# MSS_CSI2 register map
Vendor: Texas Instruments
Peripheral module from a debugger description file (folder awr2x44p).
Registers are 32-bit, access per field, no defined reset value unless marked. A register's access mark holds for its fields unless they carry their own. Offsets are as the file gives them; lines under a group give offsets from that group; [hi:lo] are bit positions; {n}, {i} and the like mark numbered series; 'fields as' and 'values as' point back to an identical list; <NAME> marks a mode.

## MSS_CSI2
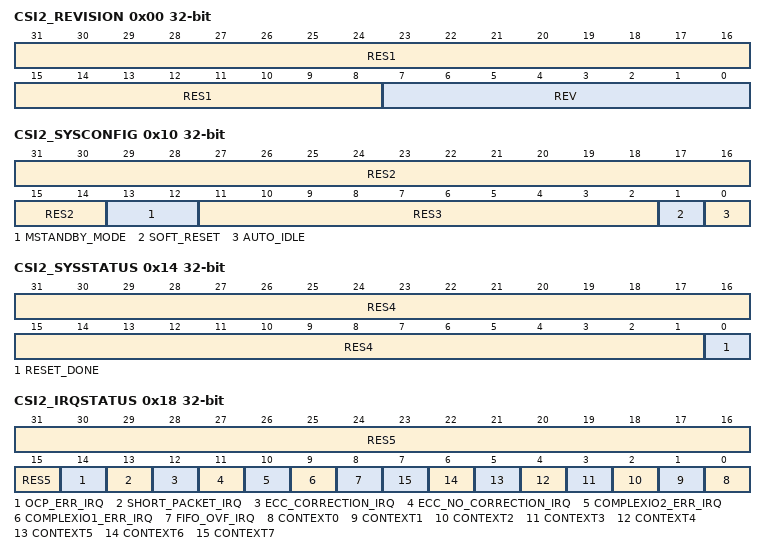
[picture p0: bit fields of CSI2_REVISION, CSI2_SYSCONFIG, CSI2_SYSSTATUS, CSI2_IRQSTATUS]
0x00 CSI2_REVISION ro — MODULE REVISION This register contains the IP revision code in binary coded digital. For example we have: 0x01 = revision 0.1 and 0x21 = revision 2.1
  [31:8] RES1 — RESERVE FIELD
  [7:0] REV — IP revision [7:4] Major revision [3:0] Minor revision
0x10 CSI2_SYSCONFIG — SYSTEM CONFIGURATION REGISTER This register is the OCP-socket system configuration register.
  [31:14] RES2 ro — RESERVE FIELD
  [13:12] MSTANDBY_MODE rw — RESERVE FIELD
  [11:2] RES3 ro — RESERVE FIELD
  [1] SOFT_RESET rw — Software reset. Set the bit to 1 to trigger a module reset. The bit is automatically reset by the hw. During reads return 0. 0: Normal mode. 1: The module is reset
  [0] AUTO_IDLE rw — Internal OCP gating strategy 0: OCP clock is free-running. 1: Automatic OCP clock gating strategy is applied based on the OCP interface activity.
0x14 CSI2_SYSSTATUS ro — SYSTEM STATUS REGISTER This register provides status information about the module excluding the interrupt status register.
  [31:1] RES4 — RESERVE FIELD
  [0] RESET_DONE — Internal reset monitoring Read 0x1: Reset completed. Read 0x0: Internal module reset is on going.
0x18 CSI2_IRQSTATUS — INTERRUPT STATUS REGISTER - All contexts This register associates one bit for each context in order to determine which context has generated the interrupt. The context shall be enabled for events to be generated on that context. If the
  [31:15] RES5 ro — RESERVE FIELD
  [14] OCP_ERR_IRQ rw — OCP Error Interrupt 0: READS: Event is false. WRITES: Status bit unchanged. 1: READS: Event is true (pending). WRITES: Status bit is reset. (RW W1toClr)
  [13] SHORT_PACKET_IRQ rw — Short packet reception status (other than synch events: Line Start, Line End, Frame Start, and Frame End: data type between 0x8 and x0F only shall be considered). 0: READS: Event is false. WRITES: Status bit unchanged. 1: READS: Event is true (pending). WRITES: Status bit is reset. (RW W1toClr)
  [12] ECC_CORRECTION_IRQ rw — ECC has been used to do the correction of the only 1-bit error status (short packet only). 0: READS: Event is false. WRITES: Status bit unchanged. 1: READS: Event is true (pending). WRITES: Status bit is reset. - (RW W1toClr)
  [11] ECC_NO_CORRECTION_IRQ rw — ECC error status (short and long packets). No correction of the header because of more than 1-bit error. 0: READS: Event is false. WRITES: Status bit unchanged. 1: READS: Event is true (pending). WRITES: Status bit is reset. - (RW W1toClr)
  [10] COMPLEXIO2_ERR_IRQ ro — RESERVE FIELD
  [9] COMPLEXIO1_ERR_IRQ ro — Error signaling from Complex IO #1: status of the PHY errors received from the complex IO #1 (events are defined in CSI2_COMPLEXIO1_IRQSTATUS for the 1st complex IO). Read 0: READS: Event is false. Read 1: READS: Event is true (pending).
  [8] FIFO_OVF_IRQ rw — FIFO overflow error status. 0: READS: Event is false. WRITES: Status bit unchanged. 1: READS: Event is true (pending). WRITES: Status bit is reset. - (RW W1toClr)
  [n] CONTEXT{n} ro (n=0..7) — Context {n} Read 0: READS: Event is false. Read 1: READS: Event is true (pending).
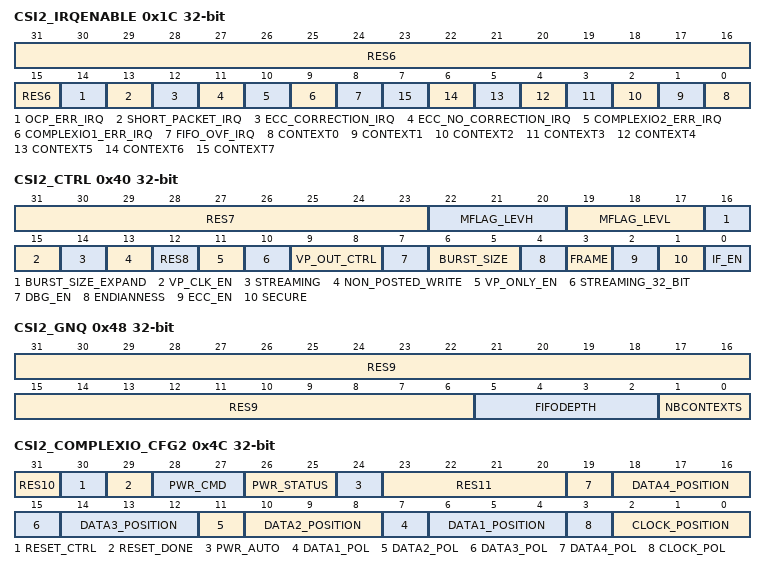
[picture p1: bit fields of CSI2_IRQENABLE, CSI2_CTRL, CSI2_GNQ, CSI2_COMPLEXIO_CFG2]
0x1C CSI2_IRQENABLE — INTERRUPT ENABLE REGISTER - All contexts This register associates one bit for each context in order to enable/disable each context individually.
  [31:15] RES6 ro — RESERVE FIELD
  [14] OCP_ERR_IRQ rw — OCP Error Interrupt 0: Event is masked 1: Event generates an interrupt when it occurs
  [13] SHORT_PACKET_IRQ rw — Short packet reception (other than synch events: Line Start, Line End, Frame Start, and Frame End: data type between 0x8 and x0F only shall be considered). 0: Event is masked 1: Event generates an interrupt when it occurs
  [12] ECC_CORRECTION_IRQ rw — ECC has been used to correct the only 1-bit error (short packet only). 0: Event is masked 1: Event generates an interrupt when it occurs
  [11] ECC_NO_CORRECTION_IRQ rw — ECC error (short and long packets). No correction of the header because of more than 1-bit error. 0: Event is masked 1: Event generates an interrupt when it occurs
  [10] COMPLEXIO2_ERR_IRQ rw — RESERVED
  [9] COMPLEXIO1_ERR_IRQ rw — Error signaling from Complex IO #1: the interrupt is triggered when any error is received from the complex IO #1 (events are defined in CSI2_COMPLEXIO1_IRQSTATUS for the 1st complex IO). 0: Event is masked 1: Event generates an interrupt when it occurs
  [8] FIFO_OVF_IRQ rw — FIFO overflow enable 0: Event is masked 1: Event generates an interrupt when it occurs
  [n] CONTEXT{n} rw (n=0..7) — Context {n} 0: Event is masked 1: Event generates an interrupt when it occurs
0x40 CSI2_CTRL — GLOBAL CONTROL REGISTER This register controls the CSI2 RECEIVER module. This register shall not be modified dynamically (except IF_EN bit field).
  [31:23] RES7 ro — RESERVE FIELD
  [22:20] MFLAG_LEVH rw — RESERVE FIELD
  [19:17] MFLAG_LEVL rw — RESERVE FIELD
  [16] BURST_SIZE_EXPAND rw — Sets the DMA burst size on the L3 interconnect. 0: Use the burst size defined in the BURST_SIZE register 1: Allow generation of 16x64-bit bursts
  [15] VP_CLK_EN rw — RESERVE FIELD
  [14] STREAMING rw — Streaming mode 0: Disable 1: Enable
  [13] NON_POSTED_WRITE rw — Not Posted Writes 0: Disable 1: Enable
  [12] RES8 ro — RESERVE FIELD
  [11] VP_ONLY_EN rw — RESERVE FIELD
  [10] STREAMING_32_BIT rw — Indicates if 64-bit or 32-bit streaming burst is used. Valid only if CSI2_CTRL.STREAMING=1 0: 64-bit streaming burst is used; byte enable pattern is 0xFF 1: 32-bit streaming burst is used; byte enable pattern is 0x0F
  [9:8] VP_OUT_CTRL rw — RESERVE FIELD
  [7] DBG_EN rw — Enables the debug mode. 0: Disable 1: Enable
  [6:5] BURST_SIZE rw — Sets the DMA burst size on the L3 interconnect. 0x0: 1x64 OCP writes 0x1: 2x64 OCP writes 0x2: 4x64 OCP writes 0x3: 8x64 OCP writes
  [4] ENDIANNESS rw — Select endianness for YUV422 8 bit and YUV420 legacy formats. 0: Use native MIPI CSI2 endianness: Little endian for all formats except for YUV422 8b and YUV420 Legacy which a big endian. 1: Store all pixel formats little endian.
  [3] FRAME rw — Set the modality in which IF_EN works. 0: If IF_EN = 0 the interface is disabled immediately. 1: If IF_EN = 1 the interface is disabled after all FEC sync code have been received for the active contexts.
  [2] ECC_EN rw — Enables the Error Correction Code check for the received header (short and long packets for all virtual channel ids). 0: Disabled 1: Enabled
  [1] SECURE rw — RESERVE FIELD
  [0] IF_EN rw — Enables the physical interface to the module. 0: The interface is disabled. If FRAME = 0, it is disabled immediately. If FRAME = 1, it is disabled when each context has received the FEC sync code. 1: The interface is enabled immediately, the data acquisition starts on the next FSC sync code. Writing '1' to this register when the current value is '0' has the effect to clear the output FIFO. The pixel data of the following frame will be written in the PING buffer, i.e., the CSI2_CTX_CTRL.PING_PONG bits are reset to '0' as well.
0x44 CSI2_DBG_H wo — DEBUG REGISTER (Header) This register provides a way to debug the CSI2 RECEIVER module with no image sensor connected to the module. The debug mode is enabled by CSI2_CTRL.DBG_EN. Only full 32-bit values shall be written. The register is
  [31:0] DBG — 32-bit input value.
0x48 CSI2_GNQ ro — GENERIC PARAMETER REGISTER This register provide a way to read the generic parameters used in the design.
  [31:6] RES9 — RESERVE FIELD
  [5:2] FIFODEPTH — Output FIFO size in multiple of 68 bits. Read 0x2: 8x 68 bits Read 0x3: 16x 68 bits Read 0x4: 32x 68 bits Read 0x5: 64x 68 bits Read 0x6: 128 x 68 bits Read 0x7: 256 x 68 bits
  [1:0] NBCONTEXTS — Number of contexts supported by the module. Read 0x0: 1 Context Read 0x1: 2 Contexts Read 0x2: 4 Contexts Read 0x3: 8 Contexts
0x4C CSI2_COMPLEXIO_CFG2 — COMPLEX IO CONFIGURATION REGISTER for the complex IO #2 This register contains the lane configuration for the order and position of the lanes (clock and data) and the polarity order for the control of the PHY differential signals in addit
  [31] RES10 ro — RESERVE FIELD
  [30] RESET_CTRL rw — RESERVE FIELD
  [29] RESET_DONE ro — RESERVE FIELD
  [28:27] PWR_CMD rw — RESERVE FIELD
  [26:25] PWR_STATUS ro — RESERVE FIELD
  [24] PWR_AUTO rw — RESERVE FIELD
  [23:20] RES11 ro — RESERVE FIELD
  [4n+3] DATA{n}_POL rw (n=1..4) — RESERVE FIELD
  [4n+2:4n] DATA{n}_POSITION rw (n=1..4) — RESERVE FIELD
  [3] CLOCK_POL rw — RESERVE FIELD
  [2:0] CLOCK_POSITION rw — RESERVE FIELD
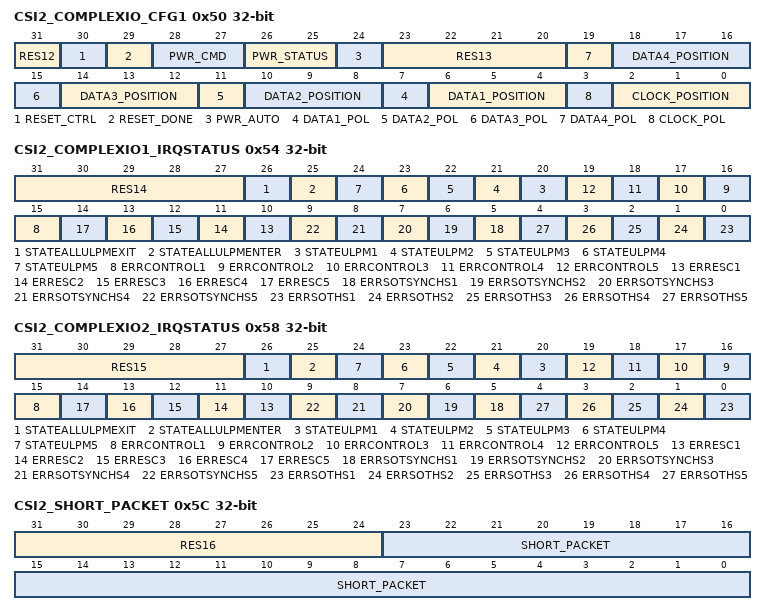
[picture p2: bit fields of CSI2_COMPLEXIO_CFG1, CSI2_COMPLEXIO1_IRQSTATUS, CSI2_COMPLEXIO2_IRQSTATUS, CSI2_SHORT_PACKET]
0x50 CSI2_COMPLEXIO_CFG1 — COMPLEXIO CONFIGURATION REGISTER for the complex IO #1 This register contains the lane configuration for the order and position of the lanes (clock and data) and the polarity order for the control of the PHY differential signals in additi
  [31] RES12 ro — RESERVE FIELD
  [30] RESET_CTRL rw — Controls the reset of the complex IO 0: Complex IO reset active. 1: Complex IO reset de-asserted.
  [29] RESET_DONE ro — Internal reset monitoring of the power domain using the PPI byte clock from the complex io Read 0: Internal module reset is on going. Read 1: Reset completed.
  [28:27] PWR_CMD rw — Command for power control of the complex io 0x0: Command to change to OFF state 0x1: Command to change to ON state 0x2: Command to change to Ultra Low Power state
  [26:25] PWR_STATUS ro — Status of the power control of the complex io Read 0x0: Complex IO in OFF state Read 0x1: Complex IO in ON state Read 0x2: Complex IO in Ultra Low Power state
  [24] PWR_AUTO rw — Automatic switch between ULP and ON states based on ULPM signals from complex iO 0: Disable 1: Enable
  [23:20] RES13 ro — RESERVE FIELD
  [4n+3] DATA{n}_POL rw (n=1..4) — +/- differential pin order of DATA lane {n}. 0: +/- pin order 1: -/+ pin order
  [18:16] DATA4_POSITION rw — Position and order of the DATA lane 4. The values 6 and 7 are reserved. 0x0: Not used/connected 0x1: Data lane 4 is at the position 1. 0x2: Data lane 4 is at the position 2. 0x3: Data lane 4 is at the position 3. 0x4: Data lane 4 is at the position 4. 0x5: Data lane 4 is at the position 5.
  [14:12] DATA3_POSITION rw — Position and order of the DATA lane 3. The values 6 and 7 are reserved. 0x0: Not used/connected 0x1: Data lane 3 is at the position 1. 0x2: Data lane 3 is at the position 2. 0x3: Data lane 3 is at the position 3. 0x4: Data lane 3 is at the position 4. 0x5: Data lane 3 is at the position 5.
  [10:8] DATA2_POSITION rw — Position and order of the DATA lane 2. The values 6 and 7 are reserved. 0x0: Not used/connected 0x1: Data lane 2 is at the position 1. 0x2: Data lane 2 is at the position 2. 0x3: Data lane 2 is at the position 3. 0x4: Data lane 2 is at the position 4. 0x5: Data lane 2 is at the position 5.
  [6:4] DATA1_POSITION rw — Position and order of the DATA lane 1. 0, 6 and 7 are reserved. The data lane 1 is always present. 0x1: Data lane 1 is at the position 1. 0x2: Data lane 1 is at the position 2. 0x3: Data lane 1 is at the position 3. 0x4: Data lane 1 is at the position 4. 0x5: Data lane 1 is at the position 5.
  [3] CLOCK_POL rw — +/- differential pin order of CLOCK lane. 0: +/- pin order 1: -/+ pin order
  [2:0] CLOCK_POSITION rw — Position and order of the CLOCK lane. 0, 6 and 7 are reserved. The clock lane is always present. 0x1: Clock lane is at the position 1. 0x2: Clock lane is at the position 2. 0x3: Clock lane is at the position 3. 0x4: Clock lane is at the position 4. 0x5: Clock lane is at the position 5.
0x54 CSI2_COMPLEXIO1_IRQSTATUS — INTERRUPT STATUS REGISTER - All errors from complex IO #1
  [31:27] RES14 ro — RESERVE FIELD
  [26] STATEALLULPMEXIT rw — At least one of the active lanes has exit the ULPM 0: READS: Event is false. WRITES: Status bit unchanged. 1: READS: Event is true (pending). WRITES: Status bit is reset. - (RW W1toClr)
  [25] STATEALLULPMENTER rw — All active lanes are entering in ULPM. 0: READS: Event is false. WRITES: Status bit unchanged. 1: READS: Event is true (pending). WRITES: Status bit is reset. - (RW W1toClr)
  [n+19] STATEULPM{n} rw (n=1..5) — Lane #{n} in Ultra Low Power Mode 0: READS: Event is false. WRITES: Status bit unchanged. 1: READS: Event is true (pending). WRITES: Status bit is reset. - (RW W1toClr)
  [n+14] ERRCONTROL{n} rw (n=1..5) — Control error for lane #{n} 0: READS: Event is false. WRITES: Status bit unchanged. 1: READS: Event is true (pending). WRITES: Status bit is reset. - (RW W1toClr)
  [n+9] ERRESC{n} rw (n=1..5) — Escape entry error for lane #{n} 0: READS: Event is false. WRITES: Status bit unchanged. 1: READS: Event is true (pending). WRITES: Status bit is reset. - (RW W1toClr)
  [n+4] ERRSOTSYNCHS{n} rw (n=1..5) — Start of transmission sync error for lane #{n} 0: READS: Event is false. WRITES: Status bit unchanged. 1: READS: Event is true (pending). WRITES: Status bit is reset. - (RW W1toClr)
  [n-1] ERRSOTHS{n} rw (n=1..5) — Start of transmission error for lane #{n} 0: READS: Event is false. WRITES: Status bit unchanged. 1: READS: Event is true (pending). WRITES: Status bit is reset. - (RW W1toClr)
0x58 CSI2_COMPLEXIO2_IRQSTATUS — INTERRUPT STATUS REGISTER - All errors from complex IO #2
  [31:27] RES15 ro — RESERVE FIELD
  [26] STATEALLULPMEXIT rw — RESERVE FIELD
  [25] STATEALLULPMENTER rw — RESERVE FIELD
  [n+19] STATEULPM{n} rw (n=1..5) — RESERVE FIELD
  [n+14] ERRCONTROL{n} rw (n=1..5) — RESERVE FIELD
  [n+9] ERRESC{n} rw (n=1..5) — RESERVE FIELD
  [n+4] ERRSOTSYNCHS{n} rw (n=1..5) — RESERVE FIELD
  [n-1] ERRSOTHS{n} rw (n=1..5) — RESERVE FIELD
0x5C CSI2_SHORT_PACKET ro — SHORT PACKET INFORMATION - This register sets the 24-bit DATA_ID + Short Packet Data Field when the data type is between 0x8 and x0F
  [31:24] RES16 — RESERVE FIELD
  [23:0] SHORT_PACKET — Short Packet information: DATA ID + DATA FIELD
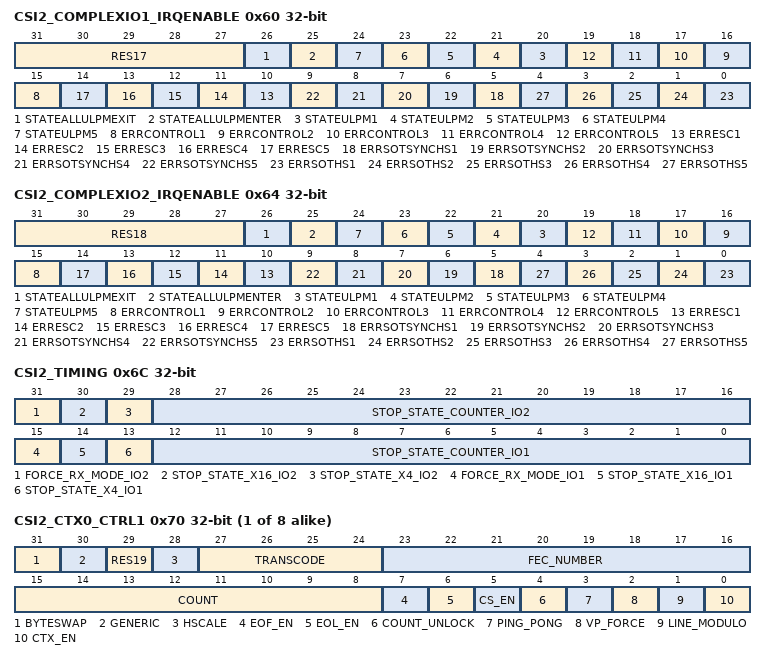
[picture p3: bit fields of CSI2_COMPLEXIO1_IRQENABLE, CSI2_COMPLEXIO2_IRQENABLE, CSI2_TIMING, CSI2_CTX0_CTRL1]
0x60 CSI2_COMPLEXIO1_IRQENABLE — INTERRUPT ENABLE REGISTER - All errors from complex IO #1
  [31:27] RES17 ro — RESERVE FIELD
  [26] STATEALLULPMEXIT rw — At least one of the active lanes has exit the ULPM 0: Event is masked 1: Event generates an interrupt when it occurs
  [25] STATEALLULPMENTER rw — All active lanes are entering in ULPM. 0: Event is masked 1: Event generates an interrupt when it occurs
  [n+19] STATEULPM{n} rw (n=1..5) — Lane #{n} in Ultra Low Power Mode 0: Event is masked 1: Event generates an interrupt when it occurs
  [n+14] ERRCONTROL{n} rw (n=1..5) — Control error for lane #{n} 0: Event is masked 1: Event generates an interrupt when it occurs
  [n+9] ERRESC{n} rw (n=1..5) — Escape entry error for lane #{n} 0: Event is masked 1: Event generates an interrupt when it occurs
  [n+4] ERRSOTSYNCHS{n} rw (n=1..5) — Start of transmission sync error for lane #{n} 0: Event is masked 1: Event generates an interrupt when it occurs
  [n-1] ERRSOTHS{n} rw (n=1..5) — Start of transmission error for lane #{n} 0: Event is masked 1: Event generates an interrupt when it occurs
0x64 CSI2_COMPLEXIO2_IRQENABLE — INTERRUPT ENABLE REGISTER - All errors from complex IO #2
  [31:27] RES18 ro — RESERVE FIELD
  [26] STATEALLULPMEXIT rw — RESERVE FIELD
  [25] STATEALLULPMENTER rw — RESERVE FIELD
  [n+19] STATEULPM{n} rw (n=1..5) — RESERVE FIELD
  [n+14] ERRCONTROL{n} rw (n=1..5) — RESERVE FIELD
  [n+9] ERRESC{n} rw (n=1..5) — RESERVE FIELD
  [n+4] ERRSOTSYNCHS{n} rw (n=1..5) — RESERVE FIELD
  [n-1] ERRSOTHS{n} rw (n=1..5) — RESERVE FIELD
0x68 CSI2_DBG_P wo — DEBUG REGISTER (Payload) This register provides a way to debug the CSI2 RECEIVER module with no image sensor connected to the module. The debug mode is enabled by CSI2_CTRL.DBG_EN. Only full 32-bit values shall be written. The register is
  [31:0] DBG — 32-bit input value.
0x6C CSI2_TIMING rw — TIMING REGISTER This register controls the CSI2 RECEIVER module. This register shall not be modified while CSI2_CTRL.IF_EN is set to '1'. It is used to indicate the number of L3 cycles for the Stop State monitoring.
  [31] FORCE_RX_MODE_IO2 — RESERVE FIELD
  [30] STOP_STATE_X16_IO2 — RESERVE FIELD
  [29] STOP_STATE_X4_IO2 — RESERVE FIELD
  [28:16] STOP_STATE_COUNTER_IO2 — RESERVE FIELD
  [15] FORCE_RX_MODE_IO1 — Control of ForceRxMode signal 0: De-assertion of ForceRxMode. The HW reset the bit at the end of the Force RX Mode assertion. The SW can reset the bit in order to stop the assertion of the ForceRXMode signal prior to the completion of the period. 1: Assertion of ForceRxMode
  [14] STOP_STATE_X16_IO1 — Multiplication factor for the number of L3 cycles defined in STOP_STATE_COUNTER bit-field 0: The number of L3 cycles defined in STOP_STATE _COUNTER is multiplied by 1x 1: The number of L3 cycles defined in STOP_STATE _COUNTER is multiplied by 16x
  [13] STOP_STATE_X4_IO1 — Multiplication factor for the number of L3 cycles defined in STOP_STATE_COUNTER bit-field 0: The number of L3 cycles defined in STOP_STATE _COUNTER is multiplied by 1x 1: The number of L3 cycles defined in STOP_STATE _COUNTER is multiplied by 4x
  [12:0] STOP_STATE_COUNTER_IO1 — Stop State counter for monitoring. It indicates the number of L3 to monitor for Stop State before de-asserting ForceRxMode (Complex IO #1). The value is from 0 to 8191.
{0x70+0x20*i} CSI2_CTX{i}_CTRL1 (i=0..7) — CONTROL REGISTER - Context This register controls the Context. This register is shadowed: modifications are taken into account after the next FSC sync code.
  [31] BYTESWAP rw — Allows swapping bytes two by two in the payload data. It doesn't affect - short packets - long packet header or footers - CRC calculation The purpose is to by swap data send to the OCP port and/or video port 0: Disabled 1: Enabled
  [30] GENERIC rw — Enables the generic mode. 0: Disabled. Data is received according to CSI2_CTX_CTRL1.FORMAT and the long packet code transmitted in the MIPI stream is used. 1: Enabled. Data is received according to CSI2_CTX_CTRL1.FORMAT and the long packet code transmitted in the MIPI stream is ignored.
  [29] RES19 ro — RESERVE FIELD
  [28] HSCALE rw — Enable horizontal downscaling by a factor of two. Applies to RAW data when transcoding is enabled. Must be disabled when transcoding is disabled. 0: Disable 1: Enable
  [27:24] TRANSCODE rw — Enables image transcoding. When this features is enabled: - the data format from the camera is defined by the FORMAT register - the format after transcode is defined by the TRANSCODE register. The memory storage / video port formats is defined by the TRANSCODE register 0x0: Feature disabled. 0x1: Outputs DPCM compressed RAW10 data. After compression, pixels are coded on 8 bits. Data in memory is organized as regular RAW8 data 0x2: Outputs DPCM compressed RAW12 data. After compression, pixels are coded on 8 bits. Data in memory is organized as regular RAW8 data 0x3: Outputs ALAW compressed RAW10 data. After compression, pixels are coded on 8 bits. Data in memory is organized as regular RAW8 data. 0x4: Outputs uncompressed RAW8 data. Data in memory is organized as regular RAW8 data 0x5: Outputs uncompressed RAW10 data. Data in memory is organized as regular RAW10+EXP16 data 0x6: Outputs uncompressed RAW10 data. Data in memory is organized as regular packed RAW10 data 0x7: Outputs uncompressed RAW12 data. Data in memory is organized as regular RAW12+EXP16 data 0x8: Outputs uncompressed RAW12 data. Data in memory is organized as regular packed RAW12 data 0x9: Outputs uncompressed RAW14 data.
  [23:16] FEC_NUMBER rw — Number of FEC to receive between using swap of CSI2_CTX_DAT_PING_ADDR and CSI2_CTX_DAT_PONG_ADDR for the calculation of the address in memory. (shall be used only in interlace mode, otherwise set to '1')
  [15:8] COUNT rw — Sets the number of frame to acquire. Once the frame acquisition starts, the COUNT value is decremented after every frame. When COUNT reaches 0, the FRAME_NUMBER_IRQ interrupt is triggered and CTX_EN is set to '0'. Writes to this bit field are controlled by the COUNT_UNLOCK bit. During the same OCP write access , the bit-field COUNT_UNLOCK shall be written in addition to COUNT bit-field in order to change the COUNT value. COUNT can be overwritten dynamically with a new count value." 0: Infinite number of frames (no count). 1: 1 frame to acquire ... 255: 255 frames to acquire.
  [7] EOF_EN rw — Indicates if the end of frame signal shall be asserted at the end of the frame Read 0: The end of frame signal is not asserted at the end of each frame. Read 1: The end of frame signal is asserted at the end of each frame.
  [6] EOL_EN rw — Indicates if the end of line signal shall be asserted at the end of the line. Read 0: The end of line signal is not asserted at the end of each frame. Read 1: The end of line signal is asserted at the end of each frame.
  [5] CS_EN rw — Enables the checksum check for the received payload (long packet only). 0: Disabled 1: Enabled
  [4] COUNT_UNLOCK wo — Unlock writes to the COUNT bit field. Write 0: COUNT bit field is locked. Writes have no effect Write 1: COUNT bit field is unlocked. Writes are possible.
  [3] PING_PONG ro — Indicates whether the PING or PONG destination address (CSI2_CTX_DAT_PING_ADDR or CSI2_CTX_DAT_PONG_ADDR) was used to write the last frame. This bit field toggles after every FEC_NUMBER FEC sync code received for the current context. Read 0: PING buffer Read 1: PONG buffer
  [2] VP_FORCE rw — RESERVE FIELD
  [1] LINE_MODULO rw — Line modulo configuration 0: CSI2_CTX_CTRL3.LINE_NUMBER is used once per frame for the generation of the LINE_NUMBER_IRQ. 1: CSI2_CTX_CTRL3.LINE_NUMBER is used as a modulo number for the generation of the LINE_NUMBER_IRQ (multiple times the interrupt can be generated for each frame)
  [0] CTX_EN rw — Enables the Context 0: Disabled 1: Enabled
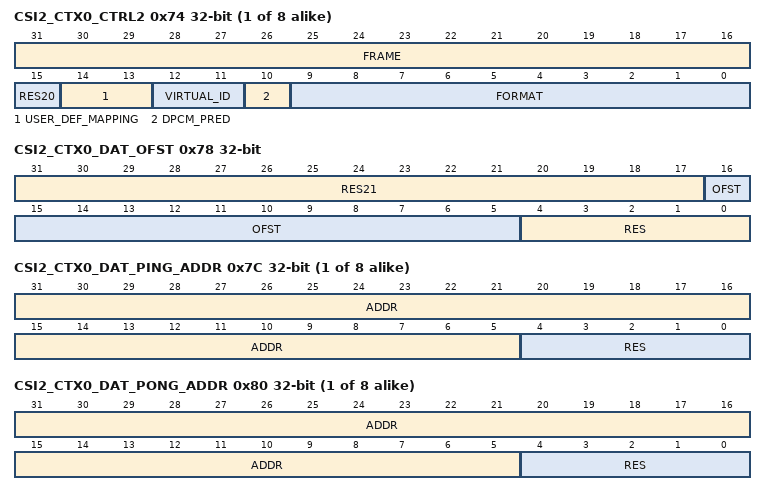
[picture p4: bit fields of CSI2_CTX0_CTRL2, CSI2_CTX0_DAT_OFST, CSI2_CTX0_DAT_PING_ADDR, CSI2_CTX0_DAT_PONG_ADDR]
{0x74+0x20*i} CSI2_CTX{i}_CTRL2 (i=0..7) — CONTROL REGISTER - Context This register controls the Context. This register is shadowed: modifications are taken into account after the next FSC sync code (except for VIRTUAL_ID and FORMAT fields). The change of VIRTUIAL_ID and FORMAT ha
  [31:16] FRAME ro — Frame number. The CSI-2 protocol engine extracts the frame number from the SOF short packet sent by the camera.
  [15] RES20 ro — RESERVE FIELD
  [14:13] USER_DEF_MAPPING rw — Selects the pixel format of USER_DEFINED in FORMAT 0x0: RAW6 0x1: RAW7 0x2: RAW8 (not valid if FORMAT is USER_DEFINED_8_BIT_DATA_TYPE_x_EXP8 with x from 1 to 8)
  [12:11] VIRTUAL_ID rw — Virtual channel ID 0x0: Virtual Channel ID 0 0x1: Virtual Channel ID 1 0x2: Virtual Channel ID 2 0x3: Virtual Channel ID 3
  [10] DPCM_PRED rw — Selects the DPCM predictor. 0: The advanced predictor is used. Not supported for 10 – 8 – 10 algorithm. Performance limited to 1 pixel/cycle. 1: The simple predictor is used.
  [9:0] FORMAT rw — Data format selection. 0x000: OTHERS (except NULL and BLANKING packets) 0x012: Embedded 8-bit non-image data (e.g. JPEG) 0x018: YUV420 8bit 0x019: YUV420 10bit 0x01A: YUV420 8bit legacy 0x01C: YUV420 8bit + CSPS 0x01D: YUV420 10bit + CSPS 0x01E: YUV422 8bit 0x01F: YUV422 10bit 0x022: RGB565 0x024: RGB888 0x028: RAW6 0x029: RAW7 0x02A: RAW8 0x02B: RAW10 0x02C: RAW12 0x02D: RAW14 0x033: RGB666 + EXP32_24 0x040: USER_DEFINED_8_BIT_DATA_TYPE_1 0x041: USER_DEFINED_8_BIT_DATA_TYPE_2 0x042: USER_DEFINED_8_BIT_DATA_TYPE_3 0x043: USER_DEFINED_8_BIT_DATA_TYPE_4 0x044: USER_DEFINED_8_BIT_DATA_TYPE_5 0x045: USER_DEFINED_8_BIT_DATA_TYPE_6 0x046: USER_DEFINED_8_BIT_DATA_TYPE_7 0x047: USER_DEFINED_8_BIT_DATA_TYPE_8 0x068: RAW6 + EXP8 0x069: RAW7 + EXP8 0x080: USER_DEFINED_8_BIT_DATA_TYPE_1 + EXP8 0x081: USER_DEFINED_8_BIT_DATA_TYPE_2 + EXP8 0x082: USER_DEFINED_8_BIT_DATA_TYPE_3 + EXP8 0x083: USER_DEFINED_8_BIT_DATA_TYPE_4 + EXP8 0x084: USER_DEFINED_8_BIT_DATA_TYPE_5 + EXP8 0x085: USER_DEFINED_8_BIT_DATA_TYPE_6 + EXP8 0x086: USER_DEFINED_8_BIT_DATA_TYPE_7 + EXP8 0x087: USER_DEFINED_8_BIT_DATA_TYPE_8 + EXP8 0x09E: YUV422 8bit + VP 0x0A0: RGB444 + EXP16 0x0A1: RGB555 + EXP16 0x0AB: RAW10 + EXP16 0x0AC: RAW12 + EXP16 0x0AD: RAW14 + EXP16 0x0DE: Same as YUV422 8bit + VP but data is send as 16-bit wide words to video port. Could be used together with the GENERIC and BYTESWAP features 0x0E3: RGB666 + EXP32 0x0E4: RGB888 + EXP32 0x0E8: RAW6 + DPCM10 + VP 0x12A: RAW8 + VP 0x12C: RAW12 + VP 0x12D: RAW14 + VP 0x12F: RAW10 + VP 0x140: USER_DEFINED_8_BIT_DATA_TYPE_1_DPCM12_VP 0x141: USER_DEFINED_8_BIT_DATA_TYPE_2_DPCM12_VP 0x142: USER_DEFINED_8_BIT_DATA_TYPE_3_DPCM12_VP 0x143: USER_DEFINED_8_BIT_DATA_TYPE_4_DPCM12_VP 0x144: USER_DEFINED_8_BIT_DATA_TYPE_5_DPCM12_VP 0x145: USER_DEFINED_8_BIT_DATA_TYPE_6_DPCM12_VP 0x146: USER_DEFINED_8_BIT_DATA_TYPE_7_DPCM12_VP 0x147: USER_DEFINED_8_BIT_DATA_TYPE_8_DPCM12_VP 0x1C0: USER_DEFINED_8_BIT_DATA_TYPE_1_DPCM12_EXP16 0x1C1: USER_DEFINED_8_BIT_DATA_TYPE_2_DPCM12_EXP16 0x1C2: USER_DEFINED_8_BIT_DATA_TYPE_3_DPCM12_EXP16 0x1C3: USER_DEFINED_8_BIT_DATA_TYPE_4_DPCM12_EXP16 0x1C4: USER_DEFINED_8_BIT_DATA_TYPE_5_DPCM12_EXP16 0x1C5: USER_DEFINED_8_BIT_DATA_TYPE_6_DPCM12_EXP16 0x1C6: USER_DEFINED_8_BIT_DATA_TYPE_7_DPCM12_EXP16 0x1C7: USER_DEFINED_8_BIT_DATA_TYPE_8_DPCM12_EXP16 0x229: RAW7 + DPCM10 + EXP16 0x2A8: RAW6 + DPCM10 + EXP16 0x2AA: RAW8 + DPCM10 + EXP16 0x2C0: USER_DEFINED_8_BIT_DATA_TYPE_1 + DPCM10 + EXP16 0x2C1: USER_DEFINED_8_BIT_DATA_TYPE_2 + DPCM10 + EXP16 0x2C2: USER_DEFINED_8_BIT_DATA_TYPE_3 + DPCM10 + EXP16 0x2C3: USER_DEFINED_8_BIT_DATA_TYPE_4 + DPCM10 + EXP16 0x2C4: USER_DEFINED_8_BIT_DATA_TYPE_5 + DPCM10 + EXP16 0x2C5: USER_DEFINED_8_BIT_DATA_TYPE_6 + DPCM10 + EXP16 0x2C6: USER_DEFINED_8_BIT_DATA_TYPE_7 + DPCM10 + EXP16 0x2C7: USER_DEFINED_8_BIT_DATA_TYPE_8 + DPCM10 + EXP16 0x329: RAW7 + DPCM10 + VP 0x32A: RAW8 + DPCM10 + VP 0x340: USER_DEFINED_8_BIT_DATA_TYPE_1 + DPCM10 + VP 0x341: USER_DEFINED_8_BIT_DATA_TYPE_2 + DPCM10 + VP 0x342: USER_DEFINED_8_BIT_DATA_TYPE_3 + DPCM10 + VP 0x343: USER_DEFINED_8_BIT_DATA_TYPE_4 + DPCM10 + VP 0x344: USER_DEFINED_8_BIT_DATA_TYPE_5 + DPCM10 + VP 0x345: USER_DEFINED_8_BIT_DATA_TYPE_6 + DPCM10 + VP 0x346: USER_DEFINED_8_BIT_DATA_TYPE_7 + DPCM10 + VP 0x347: USER_DEFINED_8_BIT_DATA_TYPE_8 + DPCM10 + VP 0x368: RAW6 DPCM12 + VP 0x369: RAW7 DPCM12 + EXP16 0x36A: RAW8 DPCM12 + EXP16 0x3A8: RAW6 DPCM12 + EXP16 0x3A9: RAW7 DPCM12 + VP 0x3AA: RAW8 DPCM12 + VP
0x78 CSI2_CTX0_DAT_OFST — DATA MEM ADDRESS OFFSET REGISTER - Context This register sets the offset which is applied on the destination address after each line is written to memory. This register applies for both CSI2_CTX_DAT_PING_ADDR and CSI2_CTX_DAT_PONG_ADDR.
  [31:17] RES21 ro — RESERVE FIELD
  [16:5] OFST rw — Line offset programmed in bytes (signed value 2's complement). If OFST = 0, the data is written contiguously in memory. Otherwise, OFST sets the destination offset between the first pixel of the previous line and the first pixel of the current line. Valid range: -2^17 ~ (2^17-1)
  [4:0] RES ro — RESERVE FIELD
{0x7C+0x20*i} CSI2_CTX{i}_DAT_PING_ADDR (i=0..7) — DATA MEM PING ADDRESS REGISTER - Context This register sets the 32-bit memory address where the pixel data are stored. The destination is double buffered: this register sets the PING address. Double buffering is enabled when the addresses
  [31:5] ADDR rw — 27 most significant bits of the 32-bit address.
  [4:0] RES ro — RESERVE FIELD
{0x80+0x20*i} CSI2_CTX{i}_DAT_PONG_ADDR (i=0..7) — DATA MEM PONG ADDRESS REGISTER - Context This register sets the 32-bit memory address where the pixel data are stored. The destination is double buffered: this register sets the PONG address. Double buffering is enabled when the addresses
  fields as CSI2_CTX0_DAT_PING_ADDR
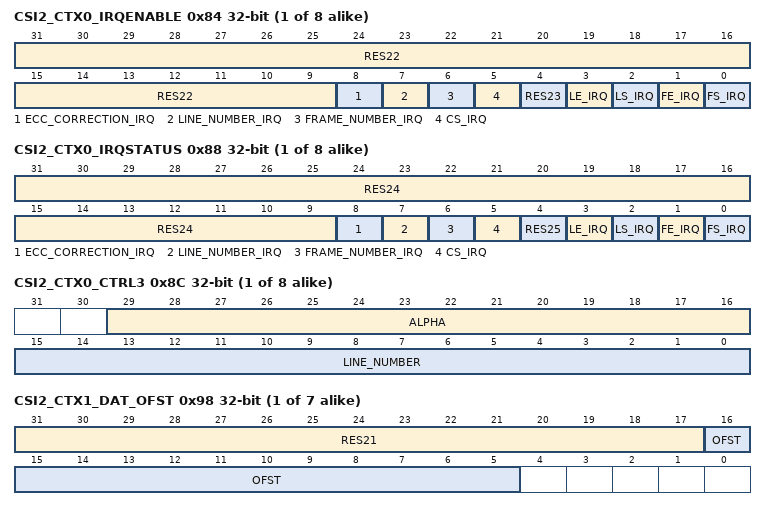
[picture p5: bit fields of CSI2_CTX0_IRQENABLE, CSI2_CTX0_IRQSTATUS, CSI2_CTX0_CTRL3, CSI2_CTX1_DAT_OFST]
{0x84+0x20*i} CSI2_CTX{i}_IRQENABLE (i=0..7) — INTERRUPT ENABLE REGISTER - Context This register regroups all the events related to Context.
  [31:9] RES22 ro — RESERVE FIELD
  [8] ECC_CORRECTION_IRQ rw — Context - ECC has been used to correct the only 1-bit error (long packet only). 0: Event is masked 1: Event generates an interrupt when it occurs
  [7] LINE_NUMBER_IRQ rw — Context - Line number is reached. 0: Event is masked 1: Event generates an interrupt when it occurs
  [6] FRAME_NUMBER_IRQ rw — Context - Frame counter reached. 0: Event is masked 1: Event generates an interrupt when it occurs
  [5] CS_IRQ rw — Context - Check-Sum of the payload mismatch detection 0: Event is masked 1: Event generates an interrupt when it occurs
  [4] RES23 ro — RESERVE FIELD
  [3] LE_IRQ rw — Context - Line end sync code detection. 0: Event is masked 1: Event generates an interrupt when it occurs
  [2] LS_IRQ rw — Context - Line start sync code detection. 0: Event is masked 1: Event generates an interrupt when it occurs
  [1] FE_IRQ rw — Context - Frame end sync code detection. 0: Event is masked 1: Event generates an interrupt when it occurs
  [0] FS_IRQ rw — Context - Frame start sync code detection. 0: Event is masked 1: Event generates an interrupt when it occurs
{0x88+0x20*i} CSI2_CTX{i}_IRQSTATUS (i=0..7) — INTERRUPT STATUS REGISTER - Context This register regroups all the events related to Context.
  [31:9] RES24 ro — RESERVE FIELD
  [8] ECC_CORRECTION_IRQ rw — Context - ECC has been used to do the correction of the only 1-bit error status (long packet only). 0: READS: Event is false. WRITES: Status bit unchanged. 1: READS: Event is true (pending). WRITES: Status bit is reset. . - (RW W1toClr)
  [7] LINE_NUMBER_IRQ rw — Contexc - Line number reached status. 0: READS: Event is false. WRITES: Status bit unchanged. 1: READS: Event is true (pending). WRITES: Status bit is reset. - (RW W1toClr)
  [6] FRAME_NUMBER_IRQ rw — Context - Frame counter reached status 0: READS: Event is false. WRITES: Status bit unchanged. 1: READS: Event is true (pending). WRITES: Status bit is reset. - (RW W1toClr)
  [5] CS_IRQ rw — Context - Check-Sum mismatch status. 0: READS: Event is false. WRITES: Status bit unchanged. 1: READS: Event is true (pending). WRITES: Status bit is reset. - (RW W1toClr)
  [4] RES25 ro — RESERVE FIELD
  [3] LE_IRQ rw — Context - Line end sync code detection status. 0: READS: Event is false. WRITES: Status bit unchanged. 1: READS: Event is true (pending). WRITES: Status bit is reset. . - (RW W1toClr)
  [2] LS_IRQ rw — Context - Line start sync code detection status. 0: READS: Event is false. WRITES: Status bit unchanged. 1: READS: Event is true (pending). WRITES: Status bit is reset. - (RW W1toClr)
  [1] FE_IRQ rw — Context - Frame end sync code detection status. 0: READS: Event is false. WRITES: Status bit unchanged. 1: READS: Event is true (pending). WRITES: Status bit is reset. - (RW W1toClr)
  [0] FS_IRQ rw — Context - Frame start sync code detection status. 0: READS: Event is false. WRITES: Status bit unchanged. 1: READS: Event is true (pending). WRITES: Status bit is reset. - (RW W1toClr)
{0x8C+0x20*i} CSI2_CTX{i}_CTRL3 (i=0..7) — CONTROL REGISTER - Context This register controls the Context. This register is shadowed: modifications are taken into account after the next FSC sync code.
  [29:16] ALPHA rw — When TRANSCODE=0 Alpha value for RGB888, RGB666 and RBG444. When TRANSCODE=1 and BYS=1 Image width, in pixels, acquired from the BYS port.
  [15:0] LINE_NUMBER rw — Line number for the interrupt generation
{0x78+0x20*i} CSI2_CTX{i}_DAT_OFST (i=1..7) — DATA MEM ADDRESS OFFSET REGISTER - Context This register sets the offset which is applied on the destination address after each line is written to memory. This register applies for both CSI2_CTX_DAT_PING_ADDR and CSI2_CTX_DAT_PONG_ADDR.
  [31:17] RES21 ro — RESERVE FIELD
  [16:5] OFST rw — Line offset programmed in bytes (signed value 2's complement). If OFST = 0, the data is written contiguously in memory. Otherwise, OFST sets the destination offset between the first pixel of the previous line and the first pixel of the current line. Valid range: -2^17 ~ (2^17-1)
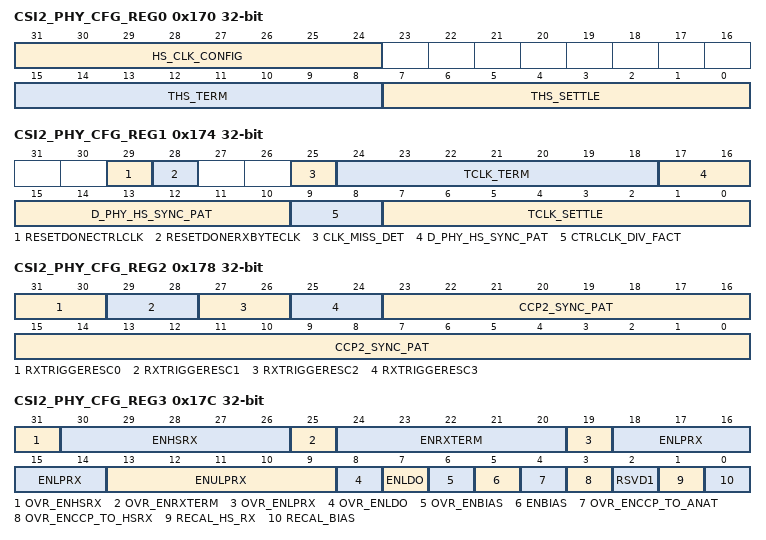
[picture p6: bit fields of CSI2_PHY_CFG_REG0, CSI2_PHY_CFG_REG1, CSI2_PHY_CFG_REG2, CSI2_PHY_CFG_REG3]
0x170 CSI2_PHY_CFG_REG0
  [31:24] HS_CLK_CONFIG rw — Disable clock missing detector
  [15:8] THS_TERM rw — Ths-term timing parameter in multiples of DDR clock. Effective time for enabling of termination= synchronizer delay + timer delay + LPRX delay + combinational routing delay ~ (1-2)* DDRCLK + THS-TERM + ~ (1-15) ns Programmed value = ceil(12.5 / DDR clock period) –1
  [7:0] THS_SETTLE rw — THS-SETTLE timing parameter in multiples on DDR clock frequency. Effective Ths-settle seen on line (starting to look for sync pattern) = synchronizer delay + timer delay + LPRX delay + combinational routing delay – pipeline delay in HS data path. ~ (1-2)* DDRCLK + THS-SETTLE + ~ (1-15) ns -1*DDRCLK Programmed value = ceil(90 ns / DDR clock period) + 3
0x174 CSI2_PHY_CFG_REG1
  [29] RESETDONECTRLCLK ro
  [28] RESETDONERXBYTECLK ro
  [25] CLK_MISS_DET ro — 1: Error in clock missing detector 0: Clock missing detector successful.
  [24:18] TCLK_TERM rw — TCLK_TERM timing parameter in multiples of CTRLCLK Effective time for enabling of termination = synchronizer delay + timer delay + LPRX delay + combinational routing delay ~ (1–2)* CTRLCLK + TCLK_TERM + ~ (1–15) ns Programmed value = ceil(9.5 / CTRLCLK period) – 1
  [17:10] D_PHY_HS_SYNC_PAT rw — DPHY mode HS sync pattern in byte order (reverse of RW 0xB8 received order) D-PHY mode sync pattern. Default : “10111000”
  [9:8] CTRLCLK_DIV_FACT rw — Divide factor for CTRLCLK for CLKMISS detector
  [7:0] TCLK_SETTLE rw — TCLK_SETTLE timing parameter in multiples of CTRLCLK Clock Effective TCLK_SETTLE = synchronizer delay + timer delay + LPRX delay + combinational routing delay ~(1–2)* CTRLCLK + Tclk-settle + ~ (1 –15) ns Programmed value = max[3, ceil(155 ns/CTRLCLK period) –1]
0x178 CSI2_PHY_CFG_REG2 rw
  [31:30] RXTRIGGERESC0 — Mapping of Trigger escape entry command to PPI output RXTRIGGERESC0
  [29:28] RXTRIGGERESC1 — Mapping of Trigger escape entry command to PPI output RXTRIGGERESC1
  [27:26] RXTRIGGERESC2 — Mapping of Trigger escape entry command to PPI output RXTRIGGERESC2.
  [25:24] RXTRIGGERESC3 — Mapping of Trigger escape entry command to PPI output RXTRIGGERESC3
  [23:0] CCP2_SYNC_PAT — CCP2 mode sync pattern in byte order (reverse of received order)
0x17C CSI2_PHY_CFG_REG3 rw
  [31] OVR_ENHSRX — RESERVE FIELD
  [30:26] ENHSRX — RESERVE FIELD
  [25] OVR_ENRXTERM — RESERVE FIELD
  [24:20] ENRXTERM — RESERVE FIELD
  [19] OVR_ENLPRX — RESERVE FIELD
  [18:14] ENLPRX — RESERVE FIELD
  [13:9] ENULPRX — RESERVE FIELD
  [8] OVR_ENLDO — RESERVE FIELD
  [7] ENLDO — RESERVE FIELD
  [6] OVR_ENBIAS — RESERVE FIELD
  [5] ENBIAS — RESERVE FIELD
  [4] OVR_ENCCP_TO_ANAT — RESERVE FIELD
  [3] OVR_ENCCP_TO_HSRX — RESERVE FIELD
  [2] RSVD1 — RESERVE FIELD
  [1] RECAL_HS_RX — RESERVE FIELD
  [0] RECAL_BIAS — RESERVE FIELD
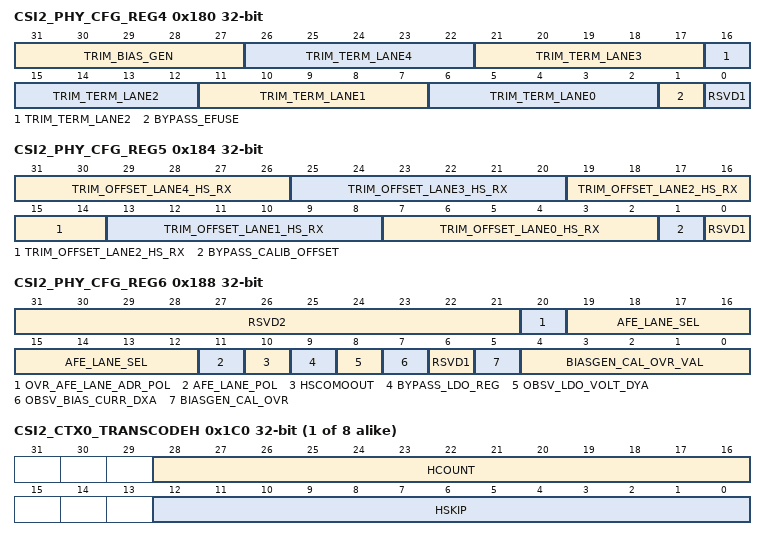
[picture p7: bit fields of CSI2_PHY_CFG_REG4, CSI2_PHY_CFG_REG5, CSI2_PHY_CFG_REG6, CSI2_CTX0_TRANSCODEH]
0x180 CSI2_PHY_CFG_REG4 rw
  [31:27] TRIM_BIAS_GEN — RESERVE FIELD
  [5n+6:5n+2] TRIM_TERM_LANE{n} (n=0..4) — RESERVE FIELD
  [1] BYPASS_EFUSE — RESERVE FIELD
  [0] RSVD1 — RESERVE FIELD
0x184 CSI2_PHY_CFG_REG5 rw
  [6n+7:6n+2] TRIM_OFFSET_LANE{n}_HS_RX (n=0..4) — RESERVE FIELD
  [1] BYPASS_CALIB_OFFSET — RESERVE FIELD
  [0] RSVD1 — RESERVE FIELD
0x188 CSI2_PHY_CFG_REG6 rw
  [31:21] RSVD2 — RESERVE FIELD
  [20] OVR_AFE_LANE_ADR_POL — RESERVE FIELD
  [19:12] AFE_LANE_SEL — RESERVE FIELD
  [11] AFE_LANE_POL — RESERVE FIELD
  [10] HSCOMOOUT — RESERVE FIELD
  [9] BYPASS_LDO_REG — RESERVE FIELD
  [8] OBSV_LDO_VOLT_DYA — RESERVE FIELD
  [7] OBSV_BIAS_CURR_DXA — RESERVE FIELD
  [6] RSVD1 — RESERVE FIELD
  [5] BIASGEN_CAL_OVR — RESERVE FIELD
  [4:0] BIASGEN_CAL_OVR_VAL — RESERVE FIELD
{0x1C0+8i} CSI2_CTX{i}_TRANSCODEH (i=0..7) — Transcode configuration register: defines horizontal frame cropping
  [28:16] HCOUNT rw — Pixels to output per line when the values is between 1 and 8191. Pixels HSKIP-WIDTH pixels are output when HCOUNT=0. WIDTH corresponds to the image width provided by the sensor.
  [12:0] HSKIP rw — Pixel to skip horizontally. Valid values: 0-8191
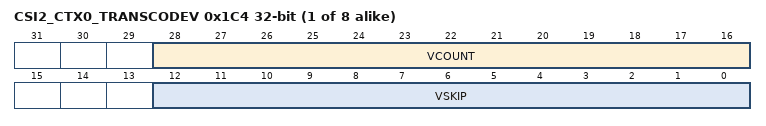
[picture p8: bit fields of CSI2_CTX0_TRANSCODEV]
{0x1C4+8i} CSI2_CTX{i}_TRANSCODEV (i=0..7) — Transcode configuration register: defines vertical frame cropping
  [28:16] VCOUNT rw — Lines to output per frame when the values is between 1 and 8191. Pixels VSKIP-HEIGHT pixels are output when VCOUNT=0. HEIGHT corresponds to the image height provided by the sensor.
  [12:0] VSKIP rw — Pixel to skip vertically Valid values: 0-8191
